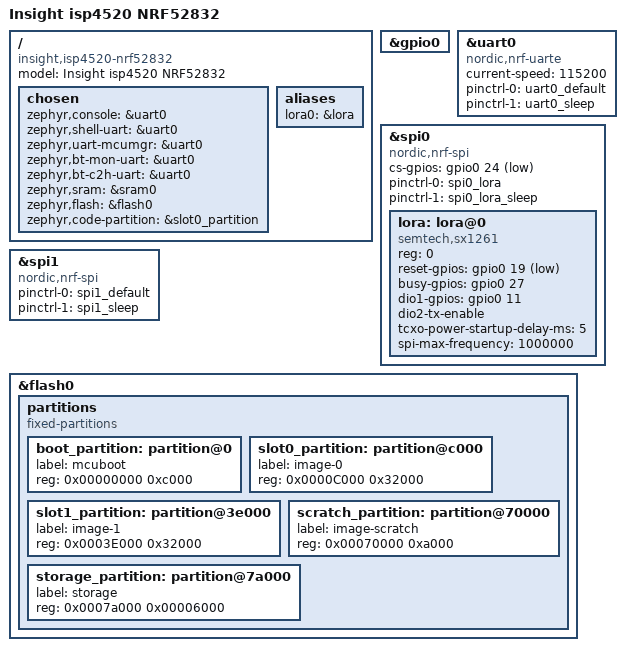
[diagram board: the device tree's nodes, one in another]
/*
 * Copyright (c) 2017 Shawn Nock <shawn@monadnock.ca>
 * Copyright (c) 2017 Linaro Limited
 *
 * SPDX-License-Identifier: Apache-2.0
 */

/dts-v1/;
#include <nordic/nrf52832_qfaa.dtsi>
#include <zephyr/dt-bindings/lora/sx126x.h>
#include "isp4520_nrf52832-pinctrl.dtsi"

/ {
	model = "Insight isp4520 NRF52832";
	compatible = "insight,isp4520-nrf52832";

	chosen {
		zephyr,console = &uart0;
		zephyr,shell-uart = &uart0;
		zephyr,uart-mcumgr = &uart0;
		zephyr,bt-mon-uart = &uart0;
		zephyr,bt-c2h-uart = &uart0;
		zephyr,sram = &sram0;
		zephyr,flash = &flash0;
		zephyr,code-partition = &slot0_partition;
	};

	/* These aliases are provided for compatibility with samples */
	aliases {
		lora0 = &lora;
	};
};

&gpio0 {
	status = "okay";
};

&uart0 {
	status = "okay";
	compatible = "nordic,nrf-uarte";
	current-speed = <115200>;
	pinctrl-0 = <&uart0_default>;
	pinctrl-1 = <&uart0_sleep>;
	pinctrl-names = "default", "sleep";
};

&spi0 {
       compatible = "nordic,nrf-spi";
       status = "okay";
	   cs-gpios = <&gpio0 24 (GPIO_PUSH_PULL | GPIO_ACTIVE_LOW)>;

       pinctrl-0 = <&spi0_lora>;
       pinctrl-1 = <&spi0_lora_sleep>;
       pinctrl-names = "default", "sleep";

       lora: lora@0 {
		compatible = "semtech,sx1261";
		reg = <0>;
		reset-gpios = <&gpio0 19 GPIO_ACTIVE_LOW>;
		//tx-enable-gpios = <&gpio0 25 GPIO_ACTIVE_LOW>;
		busy-gpios = <&gpio0 27 (GPIO_PUSH_PULL | GPIO_ACTIVE_HIGH)>;
		dio1-gpios = <&gpio0 11 (GPIO_PUSH_PULL | GPIO_ACTIVE_HIGH)>;
		dio2-tx-enable;
		//dio3-tcxo-voltage = <SX126X_DIO3_TCXO_3V0>;
		tcxo-power-startup-delay-ms = <5>;
		spi-max-frequency = <1000000>;
      };
}; 

&spi1 {
	compatible = "nordic,nrf-spi";
	status = "okay";
	pinctrl-0 = <&spi1_default>;
	pinctrl-1 = <&spi1_sleep>;
	pinctrl-names = "default", "sleep";
};

&flash0 {

	partitions {
		compatible = "fixed-partitions";
		#address-cells = <1>;
		#size-cells = <1>;

		boot_partition: partition@0 {
			label = "mcuboot";
			reg = <0x00000000 0xc000>;
		};
		slot0_partition: partition@c000 {
			label = "image-0";
			reg = <0x0000C000 0x32000>;
		};
		slot1_partition: partition@3e000 {
			label = "image-1";
			reg = <0x0003E000 0x32000>;
		};
		scratch_partition: partition@70000 {
			label = "image-scratch";
			reg = <0x00070000 0xa000>;
		};
		storage_partition: partition@7a000 {
			label = "storage";
			reg = <0x0007a000 0x00006000>;
		};
	};
};
